# STM32N655 register map
File version: 1.0
CPU: CM55 r0p1, little endian, no MPU, FPU, vendor SysTick, 8 interrupt priority bits
Registers are 32-bit, read-write, reset 0x0 unless marked. A register's access mark holds for its fields unless they carry their own. Offsets are from the block's base; [hi:lo] are bit positions; {n}, {i} and the like mark numbered series.

## GFXTIM — Graphic timer
Base 0x48004000
Same registers: GFXTIM_S 0x58004000
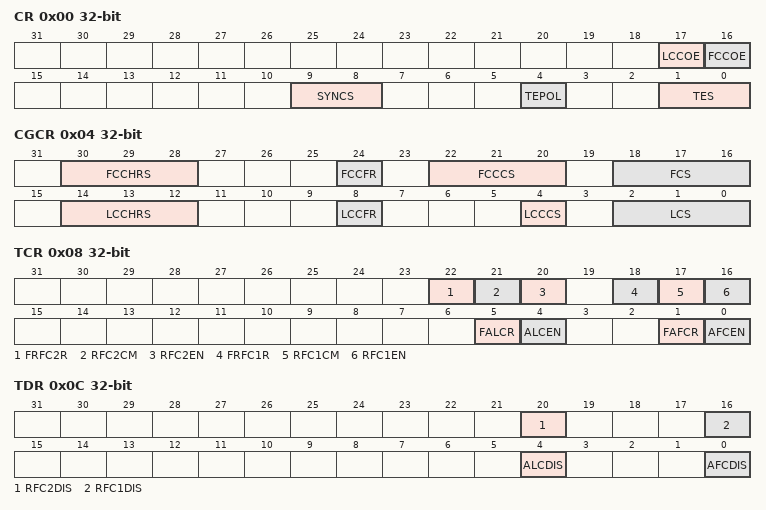
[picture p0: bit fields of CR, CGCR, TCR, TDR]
0x00 CR — GFXTIM configuration register
  [17] LCCOE — line-clock calibration output enable
  [16] FCCOE — frame-clock calibration output enable
  [9:8] SYNCS — synchronization source
  [4] TEPOL — tearing--effect polarity
  [1:0] TES — tearing source
0x04 CGCR access per field — GFXTIM clock generator configuration register
  [30:28] FCCHRS rw — frame- -clock counter hardware reload source
  [24] FCCFR wo — frame clock counter force reload
  [22:20] FCCCS rw — frame clock counter clock source
  [18:16] FCS rw — frame clock source
  [14:12] LCCHRS rw — line clock counter hardware reload source
  [8] LCCFR wo — line clock counter force reload
  [4] LCCCS rw — line clock counter clock source
  [2:0] LCS rw — line clock source
0x08 TCR access per field — GFXTIM timers configuration register
  [22] FRFC2R wo — force relative frame counter 2 reload
  [21] RFC2CM rw — relative frame counter 2 continuous mode
  [20] RFC2EN wo — relative frame counter 2 enable
  [18] FRFC1R wo — force relative frame counter 1 reload
  [17] RFC1CM rw — relative frame counter 1 continuous mode
  [16] RFC1EN wo — relative frame counter 1 enable
  [5] FALCR wo — force absolute line counter reset
  [4] ALCEN wo — absolute line counter enable
  [1] FAFCR wo — force absolute frame counter reset
  [0] AFCEN wo — absolute frame counter enable
0x0C TDR wo — GFXTIM timers disable register
  [20] RFC2DIS — relative frame counter 2 disable
  [16] RFC1DIS — relative frame counter 1 disable
  [4] ALCDIS — absolute line counter disable
  [0] AFCDIS — absolute frame counter disable
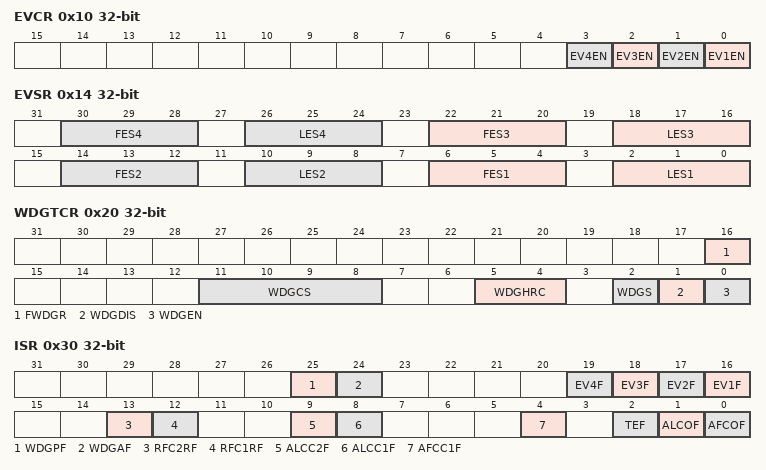
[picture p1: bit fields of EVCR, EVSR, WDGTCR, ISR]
0x10 EVCR — GFXTIM events control register
  [n-1] EV{n}EN (n=1..4) — event {n} enable
0x14 EVSR — GFXTIM events selection register
  [8n-2:8n-4] FES{n} (n=1..4) — frame-event selection {n}
  [8n-6:8n-8] LES{n} (n=1..4) — line-event selection {n}
0x20 WDGTCR access per field — GFXTIM watchdog timer configuration register
  [16] FWDGR wo — force watchdog reload
  [11:8] WDGCS rw — watchdog clock source
  [5:4] WDGHRC rw — watchdog hardware reload configuration
  [2] WDGS ro — watchdog status
  [1] WDGDIS wo — watchdog disable
  [0] WDGEN wo — watchdog enable
0x30 ISR ro — GFXTIM interrupt status register
  [25] WDGPF — watchdog pre-alarm flag
  [24] WDGAF — watchdog alarm flag
  [n+15] EV{n}F (n=1..4) — event {n} flag
  [13] RFC2RF — relative frame counter 2 reload flag
  [12] RFC1RF — relative frame counter 1 reload flag
  [9] ALCC2F — absolute line counter compare 2 flag
  [8] ALCC1F — absolute line counter compare 1 flag
  [4] AFCC1F — absolute frame counter compare 1 flag
  [2] TEF — tearing-effect flag
  [1] ALCOF — absolute line counter overflow flag
  [0] AFCOF — absolute frame counter overflow flag
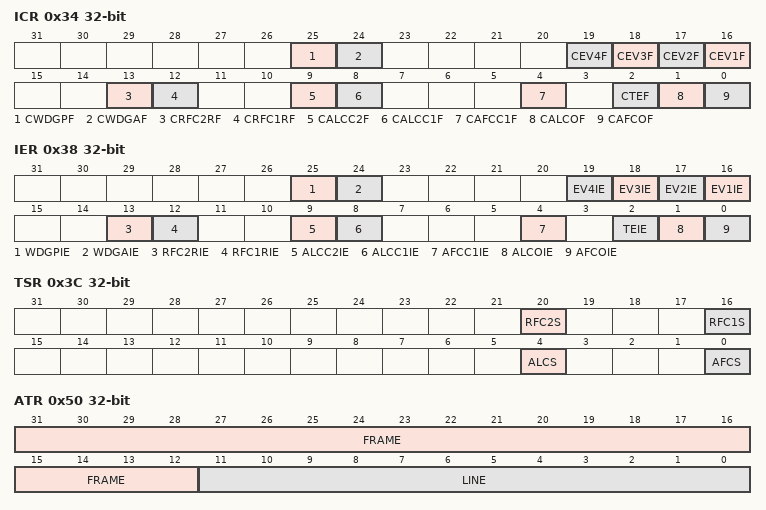
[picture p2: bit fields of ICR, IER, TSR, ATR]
0x34 ICR wo — GFXTIM interrupt clear register
  [25] CWDGPF — clear watchdog pre-alarm flag
  [24] CWDGAF — clear watchdog alarm flag
  [n+15] CEV{n}F (n=1..4) — clear event {n} flag
  [13] CRFC2RF — clear relative frame counter 2 reload flag
  [12] CRFC1RF — clear relative frame counter 1 reload flag
  [9] CALCC2F — clear absolute line counter compare 2 flag
  [8] CALCC1F — clear absolute line counter compare 1 flag
  [4] CAFCC1F — clear absolute frame counter compare 1 flag
  [2] CTEF — clear tearing-effect flag
  [1] CALCOF — clear absolute line counter overflow flag
  [0] CAFCOF — clear absolute frame counter overflow flag
0x38 IER — GFXTIM interrupt enable register
  [25] WDGPIE — watchdog pre-alarm interrupt enable
  [24] WDGAIE — watchdog alarm interrupt enable
  [n+15] EV{n}IE (n=1..4) — event {n} interrupt enable
  [13] RFC2RIE — relative frame counter 2 reload interrupt enable
  [12] RFC1RIE — relative frame counter 1 reload interrupt enable
  [9] ALCC2IE — absolute line counter compare 2 interrupt enable
  [8] ALCC1IE — absolute line counter compare 1 interrupt enable
  [4] AFCC1IE — absolute frame counter compare 1 interrupt enable
  [2] TEIE — tearing-effect interrupt enable
  [1] ALCOIE — absolute line counter overflow interrupt enable
  [0] AFCOIE — absolute frame counter overflow interrupt enable
0x3C TSR ro — GFXTIM timers status register
  [20] RFC2S — relative frame counter 2 status
  [16] RFC1S — relative frame counter 1 status
  [4] ALCS — absolute line counter status
  [0] AFCS — absolute frame counter status
0x40 LCCRR — GFXTIM line clock counter reload register
  [21:0] RELOAD — reload value
0x44 FCCRR — GFXTIM frame clock counter reload register
  [11:0] RELOAD — reload value
0x50 ATR ro — GFXTIM absolute time register
  [31:12] FRAME — fame number
  [11:0] LINE — line number
0x54 AFCR — GFXTIM absolute frame counter register
  [19:0] FRAME — frame number
0x58 ALCR — GFXTIM absolute line counter register
  [11:0] LINE — line number
0x60 AFCC1R — GFXTIM absolute frame counter compare 1 register
  [19:0] FRAME — frame number
0x70 ALCC1R — GFXTIM absolute line counter compare 1 register
  [11:0] LINE — line number
0x74 ALCC2R — GFXTIM absolute line counter compare 2 register
  [11:0] LINE — line number
0x80 RFC1R ro — GFXTIM relative frame counter 1 register
  [11:0] FRAME — frame number
0x84 RFC1RR — GFXTIM relative frame counter 1 reload register
  [11:0] FRAME — frame reload value
0x88 RFC2R ro — GFXTIM relative frame counter 2 register
  [11:0] FRAME — frame number
0x8C RFC2RR — GFXTIM relative frame counter 2 reload register
  [11:0] FRAME — frame reload value
0xA0 WDGCR ro — GFXTIM watchdog counter register
  [15:0] VALUE
0xA4 WDGRR — GFXTIM watchdog reload register
  [15:0] RELOAD — reload value
0xA8 WDGPAR — GFXTIM watchdog pre-alarm register
  [15:0] PREALARM — pre-alarm value
